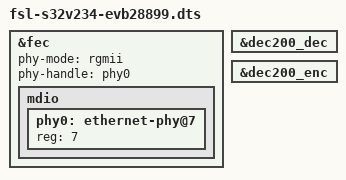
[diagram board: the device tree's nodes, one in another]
// SPDX-License-Identifier: GPL-2.0-or-later
/*
 * Copyright 2015-2016 Freescale Semiconductor, Inc.
 * Copyright 2016-2017 NXP
 */

/dts-v1/;
#include "fsl-s32v234-evb28899.dtsi"

&fec {
	phy-mode = "rgmii";
	phy-handle = <&phy0>;
	status = "okay";
	mdio {
		#address-cells = <1>;
		#size-cells = <0>;
		phy0: ethernet-phy@7 {
			reg = <7>;
		};
	};
};

&dec200_dec {
	status = "okay";
};

&dec200_enc {
	status = "okay";
};
